# ATtiny167 register map
Vendor: Atmel; File version: 1.0
CPU: other r0p0, little endian, no MPU, no FPU, 4 interrupt priority bits
Registers are 8-bit, read-write, reset 0x0 unless marked. A register's access mark holds for its fields unless they carry their own. Offsets are from the block's base; [hi:lo] are bit positions.

## LINUART — Local Interconnect Network
Base 0x000000C8
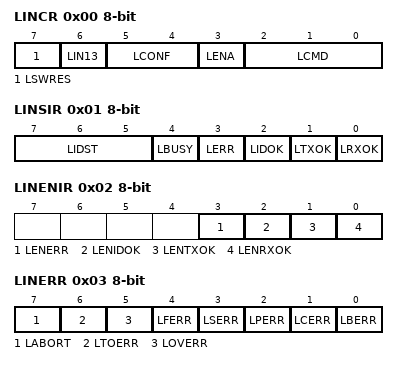
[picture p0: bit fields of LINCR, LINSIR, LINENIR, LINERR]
0x00 LINCR — LIN Control Register
  [7] LSWRES — Software Reset
  [6] LIN13 — LIN Standard
  [5:4] LCONF — LIN Configuration bits
  [3] LENA — LIN or UART Enable
  [2:0] LCMD — LIN Command and Mode bits
0x01 LINSIR — LIN Status and Interrupt Register
  [7:5] LIDST — Identifier Status bits
  [4] LBUSY — Busy Signal
  [3] LERR — Error Interrupt
  [2] LIDOK — Identifier Interrupt
  [1] LTXOK — Transmit Performed Interrupt
  [0] LRXOK — Receive Performed Interrupt
0x02 LINENIR — LIN Enable Interrupt Register
  [3] LENERR — Enable Error Interrupt
  [2] LENIDOK — Enable Identifier Interrupt
  [1] LENTXOK — Enable Transmit Performed Interrupt
  [0] LENRXOK — Enable Receive Performed Interrupt
0x03 LINERR — LIN Error Register
  [7] LABORT — Abort Flag
  [6] LTOERR — Frame Time Out Error Flag
  [5] LOVERR — Overrun Error Flag
  [4] LFERR — Framing Error Flag
  [3] LSERR — Synchronization Error Flag
  [2] LPERR — Parity Error Flag
  [1] LCERR — Checksum Error Flag
  [0] LBERR — Bit Error Flag
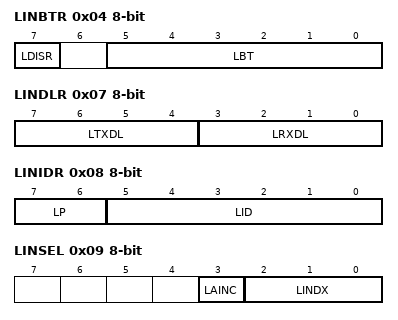
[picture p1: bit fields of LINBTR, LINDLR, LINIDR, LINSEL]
0x04 LINBTR — LIN Bit Timing Register
  [7] LDISR — Disable Bit Timing Resynchronization
  [5:0] LBT — LIN Bit Timing bits
0x05 LINBRRL — LIN Baud Rate Low Register
  [7:0] LDIV
0x06 LINBRRH — LIN Baud Rate High Register
  [3:0] LDIV
0x07 LINDLR — LIN Data Length Register
  [7:4] LTXDL — LIN Transmit Data Length bits
  [3:0] LRXDL — LIN Receive Data Length bits
0x08 LINIDR — LIN Identifier Register
  [7:6] LP — Parity bits
  [5:0] LID — Identifier bit 5 or Data Length bits
0x09 LINSEL — LIN Data Buffer Selection Register
  [3] LAINC — Auto Increment of Data Buffer Index (Active Low)
  [2:0] LINDX — FIFO LIN Data Buffer Index bits
0x0A LINDAT — LIN Data Register
  [7:0] LDATA

## LOCKBIT — Lockbits
Base 0x00000000
0x00 LOCKBIT
  [1:0] LB — Memory Lock
    0=PROG_VER_DISABLED (Further programming and verification disabled); 2=PROG_DISABLED (Further programming disabled); 3=NO_LOCK (No memory lock features enabled)

## PORTA — I/O Port
Base 0x00000020
0x00 PINA — Port A Input Pins
0x01 DDRA — Port A Data Direction Register
0x02 PORTA — Port A Data Register

## PORTB — I/O Port
Base 0x00000023
0x00 PINB — Port B Input Pins
0x01 DDRB — Port B Data Direction Register
0x02 PORTB — Port B Data Register

## SPI — Serial Peripheral Interface
Base 0x0000004C
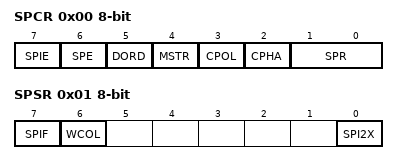
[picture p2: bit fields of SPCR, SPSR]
0x00 SPCR — SPI Control Register
  [7] SPIE — SPI Interrupt Enable
  [6] SPE — SPI Enable
  [5] DORD — Data Order
  [4] MSTR — Master/Slave Select
  [3] CPOL — Clock polarity
  [2] CPHA — Clock Phase
  [1:0] SPR — SPI Clock Rate Selects
    0=fosc/4; 1=fosc/16; 2=fosc/64; 3=fosc/128
0x01 SPSR — SPI Status Register
  [7] SPIF — SPI Interrupt Flag
  [6] WCOL — Write Collision Flag
  [0] SPI2X — Double SPI Speed Bit
0x02 SPDR — SPI Data Register

## TC0 — Timer/Counter, 8-bit Async
Base 0x00000035
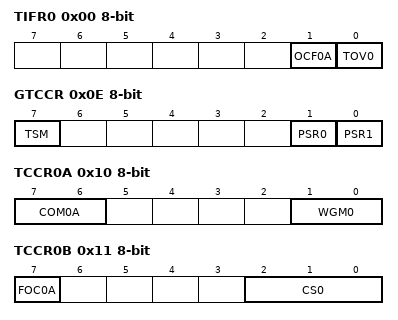
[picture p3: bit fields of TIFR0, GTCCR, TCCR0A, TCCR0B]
0x00 TIFR0 — Timer/Counter0 Interrupt Flag Register
  [1] OCF0A — Output Compare Flag 0A
  [0] TOV0 — Timer/Counter0 Overflow Flag
0x0E GTCCR — General Timer Counter Control register
  [7] TSM — Timer/Counter Synchronization Mode
  [1] PSR0 — Prescaler Reset Asynchronous 8-bit Timer/Counter0
  [0] PSR1 — Prescaler Reset Synchronous 16-bit Timer/Counter1
0x10 TCCR0A — Timer/Counter0 Control Register A
  [7:6] COM0A — Compare Output Mode bits
  [1:0] WGM0 — Waveform Genration Mode bits
0x11 TCCR0B — Timer/Counter0 Control Register B
  [7] FOC0A — Force Output Compare A
  [2:0] CS0 — Clock Select bits
    0=No Clock Source (Stopped); 1=Running, No Prescaling; 2=Running, CLK/8; 3=Running, CLK/32; 4=Running, CLK/64; 5=Running, CLK/128; 6=Running, CLK/256; 7=Running, CLK/1024
0x12 TCNT0 — Timer/Counter0
0x13 OCR0A — Timer/Counter0 Output Compare Register A
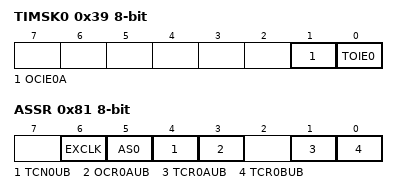
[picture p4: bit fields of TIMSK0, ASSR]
0x39 TIMSK0 — Timer/Counter0 Interrupt Mask register
  [1] OCIE0A — Timer/Counter0 Output Compare Match A Interrupt Enable
  [0] TOIE0 — Timer/Counter0 Overflow Interrupt Enable
0x81 ASSR — Asynchronous Status Register
  [6] EXCLK — Enable External Clock Input
  [5] AS0 — Asynchronous Timer/Counter0
  [4] TCN0UB — Timer/Counter0 Update Busy
  [3] OCR0AUB — Output Compare Register 0A Update Busy
  [1] TCR0AUB — Timer/Counter0 Control Register A Update Busy
  [0] TCR0BUB — Timer/Counter0 Control Register B Update Busy

## TC1 — Timer/Counter, 16-bit
Base 0x00000036
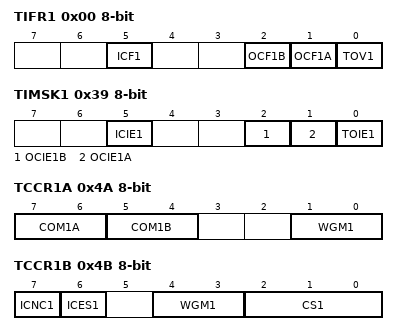
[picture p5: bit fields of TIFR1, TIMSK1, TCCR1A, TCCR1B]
0x00 TIFR1 — Timer/Counter1 Interrupt Flag register
  [5] ICF1 — Timer/Counter1 Input Capture Flag
  [2] OCF1B — Timer/Counter1 Output Compare B Match Flag
  [1] OCF1A — Timer/Counter1 Output Compare A Match Flag
  [0] TOV1 — Timer/Counter1 Overflow Flag
0x39 TIMSK1 — Timer/Counter1 Interrupt Mask Register
  [5] ICIE1 — Timer/Counter1 Input Capture Interrupt Enable
  [2] OCIE1B — Timer/Counter1 Output Compare B Match Interrupt Enable
  [1] OCIE1A — Timer/Counter1 Output Compare A Match Interrupt Enable
  [0] TOIE1 — Timer/Counter1 Overflow Interrupt Enable
0x4A TCCR1A — Timer/Counter1 Control Register A
  [7:6] COM1A — Compare Output Mode 1A, bits
  [5:4] COM1B — Compare Output Mode 1B, bits
  [1:0] WGM1 — Pulse Width Modulator Select Bits
0x4B TCCR1B — Timer/Counter1 Control Register B
  [7] ICNC1 — Input Capture 1 Noise Canceler
  [6] ICES1 — Input Capture 1 Edge Select
  [4:3] WGM1 — Waveform Generation Mode Bits
  [2:0] CS1 — Timer/Counter1 Clock Select bits
    0=No Clock Source (Stopped); 1=Running, No Prescaling; 2=Running, CLK/8; 3=Running, CLK/64; 4=Running, CLK/256; 5=Running, CLK/1024; 6=Running, ExtClk Tx Falling Edge; 7=Running, ExtClk Tx Rising Edge
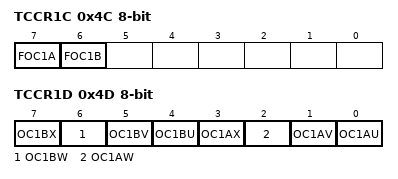
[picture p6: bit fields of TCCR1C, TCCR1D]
0x4C TCCR1C — Timer/Counter1 Control Register C
  [7] FOC1A — Timer/Counter1 Force Output Compare for Channel A
  [6] FOC1B — Timer/Counter1 Force Output Compare for Channel B
0x4D TCCR1D — Timer/Counter1 Control Register D
  [7] OC1BX — Timer/Counter1 Output Compare X-pin Enable for Channel B
  [6] OC1BW — Timer/Counter1 Output Compare W-pin Enable for Channel B
  [5] OC1BV — Timer/Counter1 Output Compare V-pin Enable for Channel B
  [4] OC1BU — Timer/Counter1 Output Compare U-pin Enable for Channel B
  [3] OC1AX — Timer/Counter1 Output Compare X-pin Enable for Channel A
  [2] OC1AW — Timer/Counter1 Output Compare W-pin Enable for Channel A
  [1] OC1AV — Timer/Counter1 Output Compare V-pin Enable for Channel A
  [0] OC1AU — Timer/Counter1 Output Compare U-pin Enable for Channel A
0x4E TCNT1 16-bit (reset mask 0xFF) — Timer/Counter1 Bytes
0x50 ICR1 16-bit (reset mask 0xFF) — Timer/Counter1 Input Capture Register Bytes
0x52 OCR1A 16-bit (reset mask 0xFF) — Timer/Counter1 Output Compare Register A Bytes
0x54 OCR1B 16-bit (reset mask 0xFF) — Timer/Counter1 Output Compare Register B Bytes

## USI — Universal Serial Interface
Base 0x000000B8
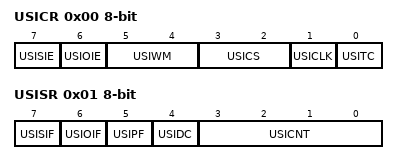
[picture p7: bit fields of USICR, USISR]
0x00 USICR — USI Control Register
  [7] USISIE — Start Condition Interrupt Enable
  [6] USIOIE — Counter Overflow Interrupt Enable
  [5:4] USIWM — USI Wire Mode Bits
    0=Normal Operation; 1=Three-Wire Mode; 2=Two-Wire Mode; 3=Two-Wire Mode Held Low
  [3:2] USICS — USI Clock Source Select Bits
  [1] USICLK — Clock Strobe
  [0] USITC — Toggle Clock Port Pin
0x01 USISR — USI Status Register
  [7] USISIF — Start Condition Interrupt Flag
  [6] USIOIF — Counter Overflow Interrupt Flag
  [5] USIPF — Stop Condition Flag
  [4] USIDC — Data Output Collision
  [3:0] USICNT — USI Counter Value Bits
0x02 USIDR — USI Data Register
0x03 USIBR — USI Buffer Register
0x04 USIPP — USI Pin Position

## WDT — Watchdog Timer
Base 0x00000060
0x00 WDTCR — Watchdog Timer Control Register
  [7] WDIF — Watchdog Timeout Interrupt Flag
  [6] WDIE — Watchdog Timeout Interrupt Enable
  [4] WDCE — Watchdog Change Enable
  [3] WDE — Watch Dog Enable
  [5:0] WDP — Watchdog Timer Prescaler Bits
    0=Oscillator Cycles 2K; 1=Oscillator Cycles 4K; 2=Oscillator Cycles 8K; 3=Oscillator Cycles 16K; 4=Oscillator Cycles 32K; 5=Oscillator Cycles 64K; 6=Oscillator Cycles 128K; 7=Oscillator Cycles 256K
